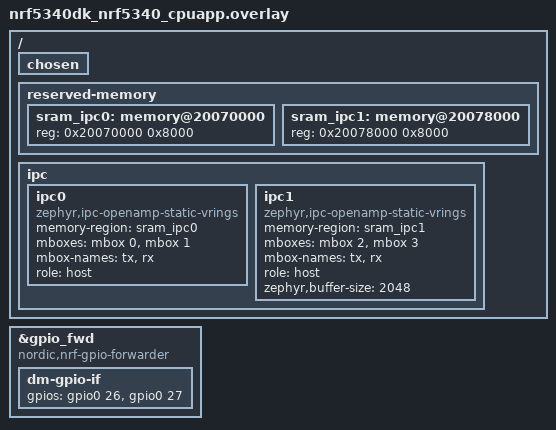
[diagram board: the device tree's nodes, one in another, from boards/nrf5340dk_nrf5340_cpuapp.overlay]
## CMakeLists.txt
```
#
# Copyright (c) 2019 Nordic Semiconductor ASA
#
# SPDX-License-Identifier: LicenseRef-Nordic-5-Clause
#
cmake_minimum_required(VERSION 3.20.0)

find_package(Zephyr REQUIRED HINTS $ENV{ZEPHYR_BASE})
project(DM_Server)

# NORDIC SDK APP START
target_sources(app PRIVATE
	src/main.c
	src/model_handler.c)
target_include_directories(app PRIVATE include)

# NORDIC SDK APP END
```

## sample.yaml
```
sample:
  description: Bluetooth Mesh light sample
  name: Bluetooth Mesh light
tests:
  sample.bluetooth.mesh.light:
    build_only: true
    integration_platforms:
      - nrf52dk_nrf52832
      - nrf52840dk_nrf52840
      - nrf52833dk_nrf52833
      - nrf5340dk_nrf5340_cpuapp
      - nrf5340dk_nrf5340_cpuapp_ns
      - thingy53_nrf5340_cpuapp
      - nrf21540dk_nrf52840
    platform_allow: nrf52dk_nrf52832 nrf52840dk_nrf52840 nrf5340dk_nrf5340_cpuapp
      nrf5340dk_nrf5340_cpuapp_ns thingy53_nrf5340_cpuapp
      nrf21540dk_nrf52840 nrf52833dk_nrf52833
    tags: bluetooth ci_build
  sample.bluetooth.mesh.light.dfu:
    build_only: true
    integration_platforms:
      - nrf52840dk_nrf52840
      - nrf21540dk_nrf52840
    platform_allow: nrf52840dk_nrf52840 nrf21540dk_nrf52840
    extra_args: OVERLAY_CONFIG=overlay-dfu.conf
    tags: bluetooth ci_build
```

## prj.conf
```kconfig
CONFIG_NCS_SAMPLES_DEFAULTS=y

# Deffered logging helps improve LPN power consumption
# when friendship is established.
CONFIG_LOG_MODE_DEFERRED=y

# General configuration
CONFIG_SYSTEM_WORKQUEUE_STACK_SIZE=2048
CONFIG_FLASH=y
CONFIG_FLASH_MAP=y
CONFIG_NVS=y
CONFIG_SETTINGS=y
CONFIG_NVS_LOOKUP_CACHE=y
CONFIG_SETTINGS_NVS_NAME_CACHE=y
CONFIG_HWINFO=y
CONFIG_DK_LIBRARY=y
CONFIG_PM_SINGLE_IMAGE=y
CONFIG_PM_PARTITION_SIZE_SETTINGS_STORAGE=0x8000
CONFIG_SOC_FLASH_NRF_PARTIAL_ERASE=y

# This is new I want to see if this will fix errors with CONFIG_BT_MESH_DM_SRV (Do I need to put this in the child_image config file?)
CONFIG_NEWLIB_LIBC=y

# Bluetooth configuration
CONFIG_BT=y
CONFIG_BT_DEVICE_NAME="Mesh Distance Server"
CONFIG_BT_L2CAP_TX_BUF_COUNT=8

CONFIG_BT_OBSERVER=y
CONFIG_BT_PERIPHERAL=y
CONFIG_BT_SETTINGS=y
# Increase RX stack size to avoid overflow during provisioning
CONFIG_BT_RX_STACK_SIZE=2700

# Disable unused Bluetooth features
CONFIG_BT_CTLR_LE_ENC=n
CONFIG_BT_PHY_UPDATE=n
CONFIG_BT_CTLR_CHAN_SEL_2=n
CONFIG_BT_CTLR_MIN_USED_CHAN=n
CONFIG_BT_CTLR_PRIVACY=n

# Bluetooth Mesh configuration
CONFIG_BT_MESH=y
CONFIG_BT_MESH_RELAY=y
CONFIG_BT_MESH_FRIEND=y
CONFIG_BT_MESH_TX_SEG_MAX=32
CONFIG_BT_MESH_PB_GATT=y
CONFIG_BT_MESH_GATT_PROXY=y
CONFIG_BT_MESH_PROXY_USE_DEVICE_NAME=y
CONFIG_BT_MESH_DK_PROV=y

# Bluetooth Mesh models
CONFIG_DM_MODULE=y
CONFIG_MPSL=y
CONFIG_MPSL_TIMESLOT_SESSION_COUNT=2
CONFIG_BT_MESH_DM_SRV=y
```

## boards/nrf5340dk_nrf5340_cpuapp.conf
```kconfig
#CONFIG_BT_RX_STACK_SIZE=4096 This was part of the default program

# Distance Measurement (copied from NRF_DM boards 5340dk conf)
CONFIG_DM_MODULE_RPC=y
CONFIG_DM_MODULE_RPC_CLIENT=y

CONFIG_TEST_RANDOM_GENERATOR=y
CONFIG_MPSL=n

# NRF RPC
CONFIG_NRF_RPC_THREAD_POOL_SIZE=2

#SYSTEM WORKQUEUE
CONFIG_SYSTEM_WORKQUEUE_STACK_SIZE=3072

#I think I need this
#CONFIG_BT_RPC_STACK=y
```

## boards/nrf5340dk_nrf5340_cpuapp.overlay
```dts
/*
 * Copyright (c) 2022 Nordic Semiconductor ASA
 *
 * SPDX-License-Identifier: LicenseRef-Nordic-5-Clause
 */

 #include <zephyr/dt-bindings/ipc_service/static_vrings.h>

 / {
     chosen {
         /delete-property/ zephyr,ipc_shm;
     };
 
     reserved-memory {
         /delete-node/ memory@20070000;
 
         sram_ipc0: memory@20070000 {
             reg = <0x20070000 0x8000>;
         };
 
         sram_ipc1: memory@20078000 {
             reg = <0x20078000 0x8000>;
         };
     };
 
     ipc {
         /delete-node/ ipc0;
 
         ipc0: ipc0 {
             compatible = "zephyr,ipc-openamp-static-vrings";
             memory-region = <&sram_ipc0>;
             mboxes = <&mbox 0>, <&mbox 1>;
             mbox-names = "tx", "rx";
             role = "host";
             status = "okay";
         };
 
         ipc1: ipc1 {
             compatible = "zephyr,ipc-openamp-static-vrings";
             memory-region = <&sram_ipc1>;
             mboxes = <&mbox 2>, <&mbox 3>;
             mbox-names = "tx", "rx";
             role = "host";
             zephyr,buffer-size = <2048>;
             status = "okay";
         };
     };
 };
 
  /* Enable pin forwarding to network core. The selected pins will be used by
   * Distance Measurement module for debug purposes.
   *
   * Note: Pay attention to assign the same GPIO pins as those provide in network core DTS overlay.
   */
 &gpio_fwd {
     compatible = "nordic,nrf-gpio-forwarder";
     dm-gpio-if {
         gpios = <&gpio0 26 0>,
             <&gpio0 27 0>;
         };
 };
 
```

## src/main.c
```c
/** @file
 *  @brief Nordic mesh light sample
 */
#include <zephyr/bluetooth/bluetooth.h>
#include <bluetooth/mesh/models.h>
#include <bluetooth/mesh/dk_prov.h>
#include <dk_buttons_and_leds.h>
#include "model_handler.h"

static void bt_ready(int err)
{
	if (err) {
		printk("Bluetooth init failed (err %d)\n", err);
		return;
	}

	printk("Bluetooth initialized\n");

	dk_leds_init();
	dk_buttons_init(NULL);

	err = bt_mesh_init(bt_mesh_dk_prov_init(), model_handler_init());
	if (err) {
		printk("Initializing mesh failed (err %d)\n", err);
		return;
	}

	if (IS_ENABLED(CONFIG_SETTINGS)) {
		settings_load();
	}

	/* This will be a no-op if settings_load() loaded provisioning info */
	bt_mesh_prov_enable(BT_MESH_PROV_ADV | BT_MESH_PROV_GATT);

	printk("Mesh initialized\n");
}

int main(void)
{
	int err;

	printk("Initializing...\n");

	err = bt_enable(bt_ready);
	if (err) {
		printk("Bluetooth init failed (err %d)\n", err);
	}

	return 0;
}
```

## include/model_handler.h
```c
/*
 * Copyright (c) 2019 Nordic Semiconductor ASA
 *
 * SPDX-License-Identifier: LicenseRef-Nordic-5-Clause
 */

/**
 * @file
 * @brief Model handler
 */

#ifndef MODEL_HANDLER_H__
#define MODEL_HANDLER_H__

#include <zephyr/bluetooth/mesh.h>

#ifdef __cplusplus
extern "C" {
#endif

const struct bt_mesh_comp *model_handler_init(void);

#ifdef __cplusplus
}
#endif

#endif /* MODEL_HANDLER_H__ */
```

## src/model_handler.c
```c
/*
 * Copyright (c) 2019 Nordic Semiconductor ASA
 *
 * SPDX-License-Identifier: LicenseRef-Nordic-5-Clause
 */

#include <zephyr/bluetooth/bluetooth.h>
#include <bluetooth/mesh/models.h>
#include <dk_buttons_and_leds.h>
#include "model_handler.h"
#include <dm.h>
#include <bluetooth/mesh/vnd/dm_common.h>
#include <bluetooth/mesh/vnd/dm_srv.h>

#define MAX_REF_ENTRIES 1

/* DM server model setup */
static struct bt_mesh_dm_res_entry meas;

static struct bt_mesh_dm_res_entry *measurements[] = {
	&meas,
};

struct led_ctx {
	struct bt_mesh_dm_srv srv;
};

static struct led_ctx led_ctx[] = {
#if DT_NODE_EXISTS(DT_ALIAS(led0))
	{ .srv = BT_MESH_MODEL_DM_SRV_INIT(&meas, ARRAY_SIZE(measurements)) },
#endif
};

/* Set up a repeating delayed work to blink the DK's LEDs when attention is
 * requested.
 */
static struct k_work_delayable attention_blink_work;
static bool attention;

static void attention_blink(struct k_work *work)
{
	static int idx;
	const uint8_t pattern[] = {
#if DT_NODE_EXISTS(DT_ALIAS(led0))
		BIT(0),
#endif
#if DT_NODE_EXISTS(DT_ALIAS(led1))
		BIT(1),
#endif
#if DT_NODE_EXISTS(DT_ALIAS(led2))
		BIT(2),
#endif
#if DT_NODE_EXISTS(DT_ALIAS(led3))
		BIT(3),
#endif
	};

	if (attention) {
		dk_set_leds(pattern[idx++ % ARRAY_SIZE(pattern)]);
		k_work_reschedule(&attention_blink_work, K_MSEC(30));
	} else {
		dk_set_leds(DK_NO_LEDS_MSK);
	}
}

static void attention_on(const struct bt_mesh_model *mod)
{
	attention = true;
	k_work_reschedule(&attention_blink_work, K_NO_WAIT);
}

static void attention_off(const struct bt_mesh_model *mod)
{
	/* Will stop rescheduling blink timer */
	attention = false;
}

static const struct bt_mesh_health_srv_cb health_srv_cb = {
	.attn_on = attention_on,
	.attn_off = attention_off,
};

static struct bt_mesh_health_srv health_srv = {
	.cb = &health_srv_cb,
};

BT_MESH_HEALTH_PUB_DEFINE(health_pub, 0);

static struct bt_mesh_elem elements[] = {
#if DT_NODE_EXISTS(DT_ALIAS(led0))
	BT_MESH_ELEM(
		1, BT_MESH_MODEL_LIST(
			BT_MESH_MODEL_CFG_SRV,
			BT_MESH_MODEL_HEALTH_SRV(&health_srv, &health_pub)
			),
		   BT_MESH_MODEL_LIST(BT_MESH_MODEL_DM_SRV(&led_ctx[0].srv))),
#endif
};

static const struct bt_mesh_comp comp = {
	.cid = CONFIG_BT_COMPANY_ID,
	.elem = elements,
	.elem_count = ARRAY_SIZE(elements),
};

const struct bt_mesh_comp *model_handler_init(void)
{
	k_work_init_delayable(&attention_blink_work, attention_blink);
	return &comp;
}
```
